# HDSC_HC32L072KATA register map
Vendor: HDSC Co.Ltd; Series: ARMCM0P; File version: 1.2
CPU: CM0 r0p0, little endian, no MPU, no FPU, 3 interrupt priority bits
Registers are 32-bit, read-write, reset 0x0 unless marked. A register's access mark holds for its fields unless they carry their own. Offsets are from the block's base; [hi:lo] are bit positions; {n}, {i} and the like mark numbered series; 'fields as' and 'values as' point back to an identical list.

## TRNG
Base 0x40004C00
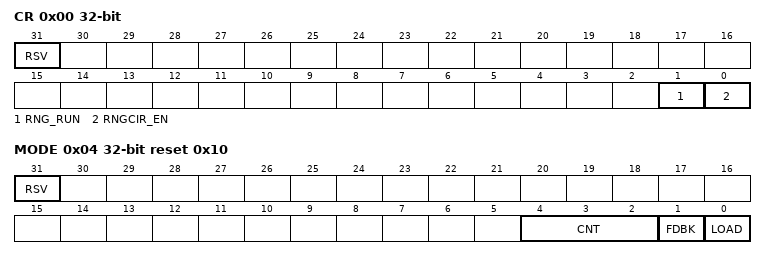
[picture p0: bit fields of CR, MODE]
0x00 CR (reset mask 0x3)
  [31] RSV, [1] RNG_RUN, [0] RNGCIR_EN
0x04 MODE reset 0x10 (reset mask 0x1F)
  [31] RSV, [4:2] CNT, [1] FDBK, [0] LOAD
0x0C DATA0 ro
0x10 DATA1 ro

## USBFS
Base 0x40040000
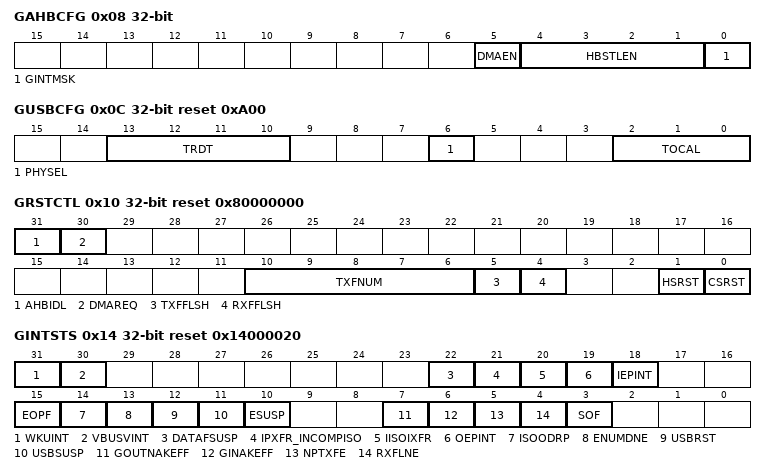
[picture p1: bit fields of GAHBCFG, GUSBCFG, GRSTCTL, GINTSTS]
0x08 GAHBCFG
  [5] DMAEN, [4:1] HBSTLEN, [0] GINTMSK
0x0C GUSBCFG reset 0xA00
  [13:10] TRDT, [6] PHYSEL, [2:0] TOCAL
0x10 GRSTCTL reset 0x80000000
  [31] AHBIDL ro, [30] DMAREQ ro, [10:6] TXFNUM, [5] TXFFLSH, [4] RXFFLSH, [1] HSRST, [0] CSRST
0x14 GINTSTS ro reset 0x14000020 (reset mask 0xC07CFCD8)
  [31] WKUINT rw, [30] VBUSVINT rw, [22] DATAFSUSP rw, [21] IPXFR_INCOMPISO rw, [20] IISOIXFR rw, [19] OEPINT, [18] IEPINT, [15] EOPF rw, [14] ISOODRP rw, [13] ENUMDNE rw, [12] USBRST rw, [11] USBSUSP rw, [10] ESUSP rw, [7] GOUTNAKEFF, [6] GINAKEFF, [5] NPTXFE, [4] RXFLNE, [3] SOF rw
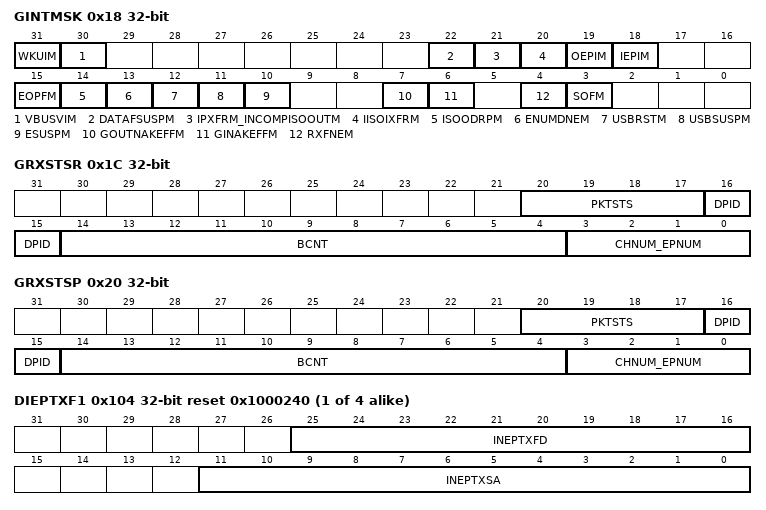
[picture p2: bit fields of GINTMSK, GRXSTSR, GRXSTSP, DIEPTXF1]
0x18 GINTMSK
  [31] WKUIM, [30] VBUSVIM, [22] DATAFSUSPM, [21] IPXFRM_INCOMPISOOUTM, [20] IISOIXFRM, [19] OEPIM, [18] IEPIM, [15] EOPFM, [14] ISOODRPM, [13] ENUMDNEM, [12] USBRSTM, [11] USBSUSPM, [10] ESUSPM, [7] GOUTNAKEFFM, [6] GINAKEFFM, [4] RXFNEM, [3] SOFM
0x1C GRXSTSR ro
  [20:17] PKTSTS, [16:15] DPID, [14:4] BCNT, [3:0] CHNUM_EPNUM
0x20 GRXSTSP ro
  [20:17] PKTSTS, [16:15] DPID, [14:4] BCNT, [3:0] CHNUM_EPNUM
0x24 GRXFSIZ reset 0x140
  [10:0] RXFD
0x3C CID ro reset 0x12345678
{0x100+4i} DIEPTXF{i} reset 0x1000240 (i=1..4)
  [25:16] INEPTXFD, [11:0] INEPTXSA
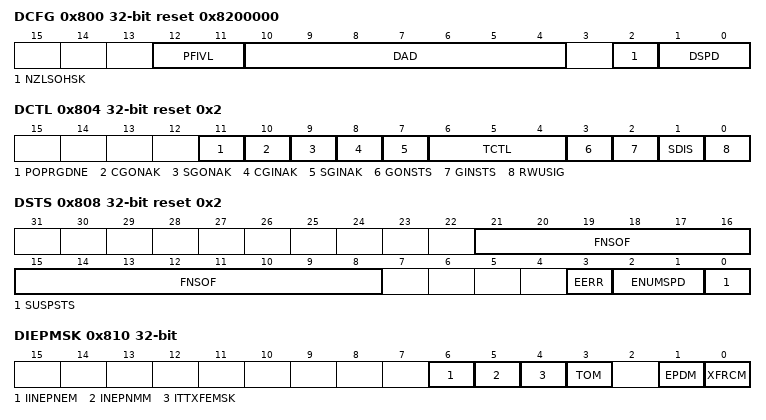
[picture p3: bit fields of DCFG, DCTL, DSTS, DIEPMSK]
0x800 DCFG reset 0x8200000
  [12:11] PFIVL, [10:4] DAD, [2] NZLSOHSK, [1:0] DSPD
0x804 DCTL reset 0x2
  [11] POPRGDNE, [10] CGONAK wo, [9] SGONAK wo, [8] CGINAK wo, [7] SGINAK wo, [6:4] TCTL, [3] GONSTS ro, [2] GINSTS ro, [1] SDIS, [0] RWUSIG
0x808 DSTS ro reset 0x2
  [21:8] FNSOF, [3] EERR, [2:1] ENUMSPD, [0] SUSPSTS
0x810 DIEPMSK
  [6] IINEPNEM, [5] INEPNMM, [4] ITTXFEMSK, [3] TOM, [1] EPDM, [0] XFRCM
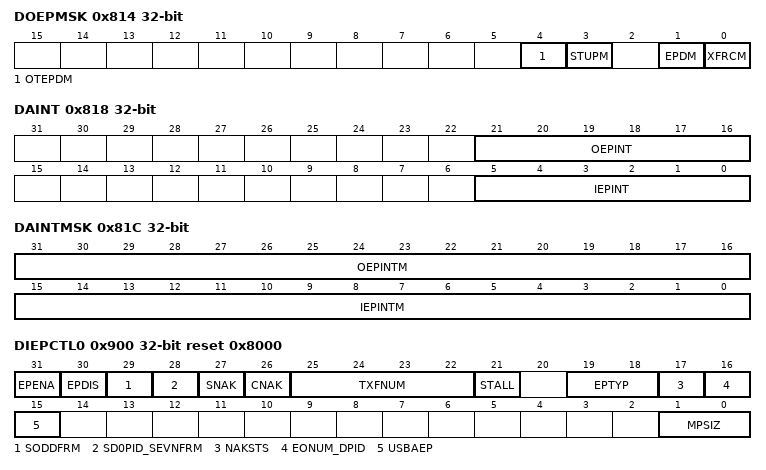
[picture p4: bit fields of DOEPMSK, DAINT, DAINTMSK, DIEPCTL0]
0x814 DOEPMSK
  [4] OTEPDM, [3] STUPM, [1] EPDM, [0] XFRCM
0x818 DAINT ro
  [21:16] OEPINT, [5:0] IEPINT
0x81C DAINTMSK ro (reset mask 0x3F003F)
  [31:16] OEPINTM, [15:0] IEPINTM
0x834 DIEPEMPMSK (reset mask 0x3F)
  [15:0] INEPTXFEM
0x900 DIEPCTL0 ro reset 0x8000 (reset mask 0xCFEE800F)
  [31] EPENA rw, [30] EPDIS, [29] SODDFRM rw, [28] SD0PID_SEVNFRM rw, [27] SNAK wo, [26] CNAK wo, [25:22] TXFNUM rw, [21] STALL rw, [19:18] EPTYP, [17] NAKSTS, [16] EONUM_DPID rw, [15] USBAEP, [1:0] MPSIZ rw
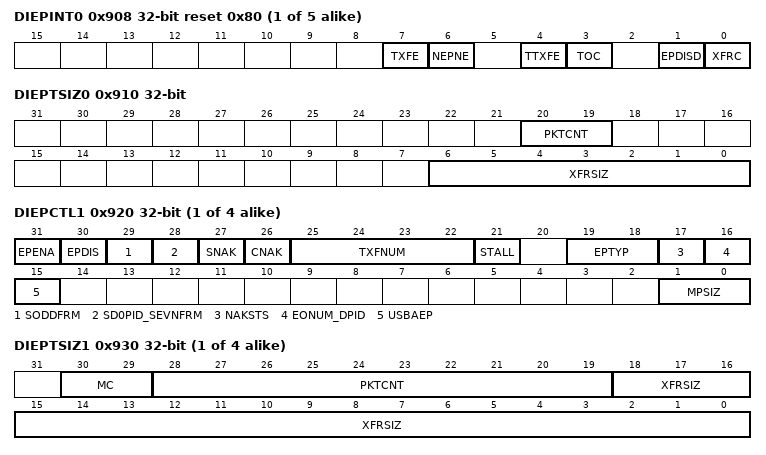
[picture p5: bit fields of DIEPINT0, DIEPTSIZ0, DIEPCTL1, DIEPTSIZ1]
{0x908+0x20*i} DIEPINT{i} reset 0x80 (i=0..4)
  [7] TXFE ro, [6] NEPNE, [4] TTXFE, [3] TOC, [1] EPDISD, [0] XFRC
0x910 DIEPTSIZ0
  [20:19] PKTCNT, [6:0] XFRSIZ
{0x914+0x20*i} DIEPDMA{i} (i=0..4)
{0x918+0x20*i} DTXFSTS{i} ro reset 0x100 (i=0..4)
  [15:0] INEPTFSAV
{0x900+0x20*i} DIEPCTL{i} (i=1..4)
  [31] EPENA, [30] EPDIS ro, [29] SODDFRM wo, [28] SD0PID_SEVNFRM wo, [27] SNAK wo, [26] CNAK wo, [25:22] TXFNUM, [21] STALL, [19:18] EPTYP ro, [17] NAKSTS ro, [16] EONUM_DPID ro, [15] USBAEP ro, [1:0] MPSIZ
{0x910+0x20*i} DIEPTSIZ{i} (i=1..4)
  [30:29] MC, [28:19] PKTCNT, [18:0] XFRSIZ
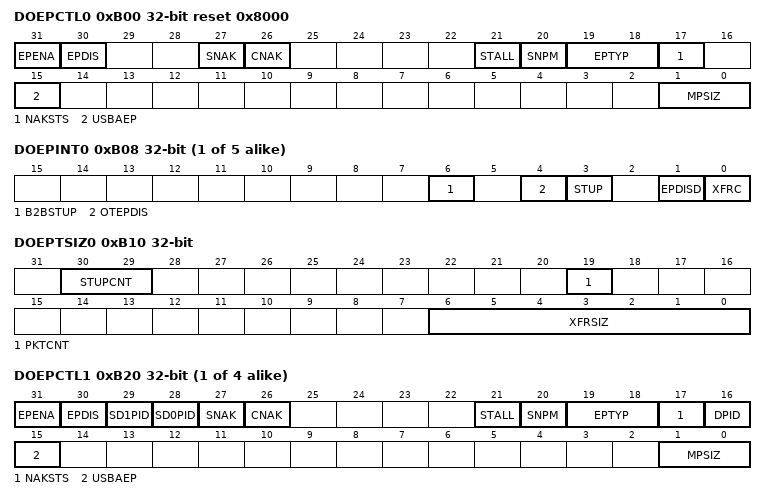
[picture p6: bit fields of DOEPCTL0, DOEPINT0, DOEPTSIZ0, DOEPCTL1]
0xB00 DOEPCTL0 ro reset 0x8000
  [31] EPENA rw, [30] EPDIS, [27] SNAK wo, [26] CNAK wo, [21] STALL rw, [20] SNPM rw, [19:18] EPTYP, [17] NAKSTS, [15] USBAEP, [1:0] MPSIZ
{0xB08+0x20*i} DOEPINT{i} (i=0..4)
  [6] B2BSTUP, [4] OTEPDIS, [3] STUP, [1] EPDISD, [0] XFRC
0xB10 DOEPTSIZ0
  [30:29] STUPCNT, [19] PKTCNT, [6:0] XFRSIZ
{0xB14+0x20*i} DOEPDMA{i} (i=0..4)
{0xB00+0x20*i} DOEPCTL{i} (i=1..4)
  [31] EPENA, [30] EPDIS ro, [29] SD1PID, [28] SD0PID, [27] SNAK wo, [26] CNAK wo, [21] STALL, [20] SNPM, [19:18] EPTYP ro, [17] NAKSTS ro, [16] DPID ro, [15] USBAEP ro, [1:0] MPSIZ
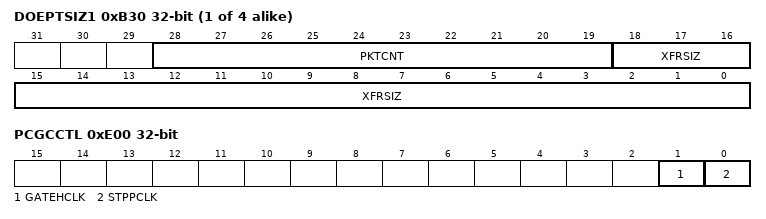
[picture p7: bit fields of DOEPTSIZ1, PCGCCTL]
{0xB10+0x20*i} DOEPTSIZ{i} (i=1..4)
  [28:19] PKTCNT, [18:0] XFRSIZ
0xE00 PCGCCTL
  [1] GATEHCLK, [0] STPPCLK

## VC
Base 0x40002400; alternate view of ADC
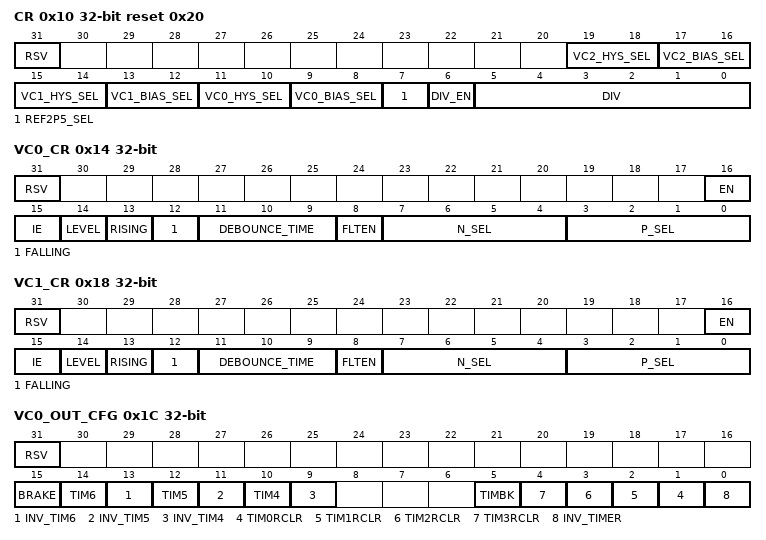
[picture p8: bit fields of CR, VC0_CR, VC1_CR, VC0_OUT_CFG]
0x10 CR reset 0x20 (reset mask 0xFFFFF)
  [31] RSV, [19:18] VC2_HYS_SEL, [17:16] VC2_BIAS_SEL, [15:14] VC1_HYS_SEL, [13:12] VC1_BIAS_SEL, [11:10] VC0_HYS_SEL, [9:8] VC0_BIAS_SEL, [7] REF2P5_SEL, [6] DIV_EN, [5:0] DIV
0x14 VC0_CR (reset mask 0x1FFFF)
  [31] RSV, [16] EN, [15] IE, [14] LEVEL, [13] RISING, [12] FALLING, [11:9] DEBOUNCE_TIME, [8] FLTEN, [7:4] N_SEL, [3:0] P_SEL
0x18 VC1_CR (reset mask 0x1FFFF)
  fields as VC0_CR
0x1C VC0_OUT_CFG (reset mask 0xFE3F)
  [31] RSV, [15] BRAKE, [14] TIM6, [13] INV_TIM6, [12] TIM5, [11] INV_TIM5, [10] TIM4, [9] INV_TIM4, [5] TIMBK, [n+1] TIM{n}RCLR (n=0..3), [0] INV_TIMER
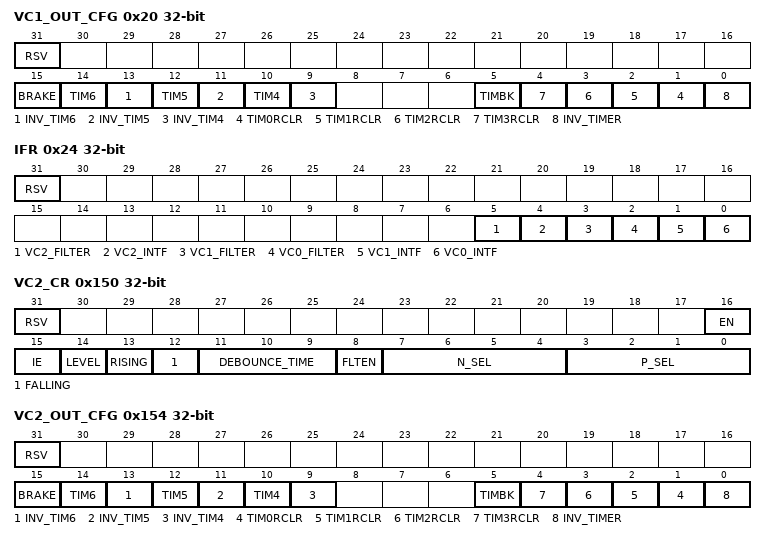
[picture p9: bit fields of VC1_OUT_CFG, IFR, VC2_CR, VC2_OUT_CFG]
0x20 VC1_OUT_CFG (reset mask 0xFEFF)
  fields as VC0_OUT_CFG
0x24 IFR (reset mask 0x3F)
  [31] RSV, [5] VC2_FILTER ro, [4] VC2_INTF, [3] VC1_FILTER ro, [2] VC0_FILTER ro, [1] VC1_INTF, [0] VC0_INTF
0x150 VC2_CR (reset mask 0x1FFFF)
  fields as VC0_CR
0x154 VC2_OUT_CFG (reset mask 0xFEFF)
  fields as VC0_OUT_CFG

## WDT
Base 0x40000F00; alternate view of LPTIMER0
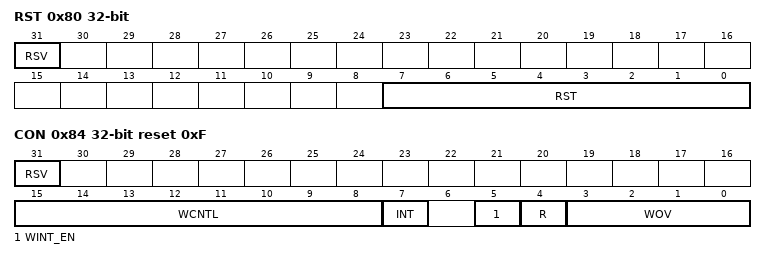
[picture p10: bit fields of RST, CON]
0x80 RST wo (reset mask 0xFF)
  [31] RSV rw, [7:0] RST
0x84 CON reset 0xF (reset mask 0xFFBF)
  [31] RSV, [15:8] WCNTL ro, [7] INT ro, [5] WINT_EN, [4] R ro, [3:0] WOV
